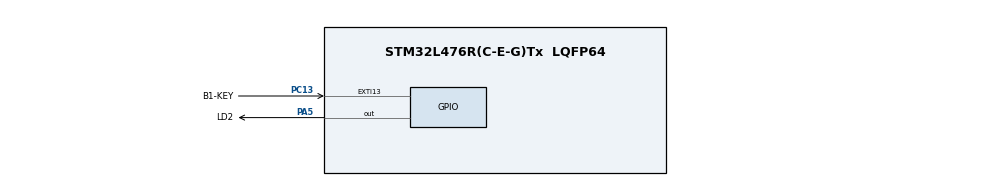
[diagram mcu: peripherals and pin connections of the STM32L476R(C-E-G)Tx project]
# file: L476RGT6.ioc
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FREERTOS.Tasks01=Start_Task,0,128,StartFunc,Default,NULL,Dynamic,NULL,NULL
Mcu.Family=STM32L4
Mcu.Name=STM32L476R(C-E-G)Tx
Mcu.Package=LQFP64
NVIC.PriorityGroup=NVIC_PRIORITYGROUP_4
NVIC.TIM1_UP_TIM16_IRQn=true\:0\:0\:false\:false\:true\:false\:false
NVIC.TimeBase=TIM1_UP_TIM16_IRQn
NVIC.TimeBaseIP=TIM1
PA5.GPIO_Label=LD2
PA5.GPIO_Speed=GPIO_SPEED_FREQ_MEDIUM
PA5.Signal=GPIO_Output
PC13.GPIO_Label=B1-KEY
PC13.GPIO_ModeDefaultEXTI=GPIO_MODE_IT_FALLING
PC13.Signal=GPXTI13
ProjectManager.HeapSize=0x200
ProjectManager.StackSize=0x400
ProjectManager.TargetToolchain=MDK-ARM V5
RCC.ADCFreq_Value=64000000
RCC.AHBFreq_Value=80000000
RCC.APB1Freq_Value=80000000
RCC.APB1TimFreq_Value=80000000
RCC.APB2Freq_Value=80000000
RCC.APB2TimFreq_Value=80000000
RCC.CortexFreq_Value=80000000
RCC.HCLKFreq_Value=80000000
RCC.HSE_VALUE=8000000
RCC.HSI_VALUE=16000000
RCC.LSE_VALUE=32768
RCC.MSI_VALUE=4000000
RCC.PLLN=10
RCC.PLLSourceVirtual=RCC_PLLSOURCE_HSI
RCC.SYSCLKFreq_VALUE=80000000
RCC.SYSCLKSource=RCC_SYSCLKSOURCE_PLLCLK
RCC.USBFreq_Value=64000000
RCC.VCOOutputFreq_Value=160000000
VP_FREERTOS_VS_ENABLE.Mode=Enabled
VP_SYS_VS_tim1.Mode=TIM1
board=custom

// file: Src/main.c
/**
  ******************************************************************************
  * @file           : main.c
  * @brief          : Main program body
  ******************************************************************************
  * This notice applies to any and all portions of this file
  * that are not between comment pairs USER CODE BEGIN and
  * USER CODE END. Other portions of this file, whether
  * inserted by the user or by software development tools
  * are owned by their respective copyright owners.
  *
  * Copyright (c) 2018 STMicroelectronics International N.V.
  * All rights reserved.
  *
  * Redistribution and use in source and binary forms, with or without
  * modification, are permitted, provided that the following conditions are met:
  *
  * 1. Redistribution of source code must retain the above copyright notice,
  *    this list of conditions and the following disclaimer.
  * 2. Redistributions in binary form must reproduce the above copyright notice,
  *    this list of conditions and the following disclaimer in the documentation
  *    and/or other materials provided with the distribution.
  * 3. Neither the name of STMicroelectronics nor the names of other
  *    contributors to this software may be used to endorse or promote products
  *    derived from this software without specific written permission.
  * 4. This software, including modifications and/or derivative works of this
  *    software, must execute solely and exclusively on microcontroller or
  *    microprocessor devices manufactured by or for STMicroelectronics.
  * 5. Redistribution and use of this software other than as permitted under
  *    this license is void and will automatically terminate your rights under
  *    this license.
  *
  * THIS SOFTWARE IS PROVIDED BY STMICROELECTRONICS AND CONTRIBUTORS "AS IS"
  * AND ANY EXPRESS, IMPLIED OR STATUTORY WARRANTIES, INCLUDING, BUT NOT
  * LIMITED TO, THE IMPLIED WARRANTIES OF MERCHANTABILITY, FITNESS FOR A
  * PARTICULAR PURPOSE AND NON-INFRINGEMENT OF THIRD PARTY INTELLECTUAL PROPERTY
  * RIGHTS ARE DISCLAIMED TO THE FULLEST EXTENT PERMITTED BY LAW. IN NO EVENT
  * SHALL STMICROELECTRONICS OR CONTRIBUTORS BE LIABLE FOR ANY DIRECT, INDIRECT,
  * INCIDENTAL, SPECIAL, EXEMPLARY, OR CONSEQUENTIAL DAMAGES (INCLUDING, BUT NOT
  * LIMITED TO, PROCUREMENT OF SUBSTITUTE GOODS OR SERVICES; LOSS OF USE, DATA,
  * OR PROFITS; OR BUSINESS INTERRUPTION) HOWEVER CAUSED AND ON ANY THEORY OF
  * LIABILITY, WHETHER IN CONTRACT, STRICT LIABILITY, OR TORT (INCLUDING
  * NEGLIGENCE OR OTHERWISE) ARISING IN ANY WAY OUT OF THE USE OF THIS SOFTWARE,
  * EVEN IF ADVISED OF THE POSSIBILITY OF SUCH DAMAGE.
  *
  ******************************************************************************
  */
#include "main.h"
#include "stm32l4xx_hal.h"
#include "cmsis_os.h"
#include "gpio.h"

/* USER CODE BEGIN PV */
/* Private variables ---------------------------------------------------------*/

/* USER CODE END PV */

void SystemClock_Config(void);
void MX_FREERTOS_Init(void);

/* USER CODE BEGIN PFP */
/* Private function prototypes -----------------------------------------------*/

/* USER CODE END PFP */

int main(void)
{

  /* MCU Configuration----------------------------------------------------------*/

  /* Reset of all peripherals, Initializes the Flash interface and the Systick. */
  HAL_Init();

  /* Configure the system clock */
  SystemClock_Config();

  /* Initialize all configured peripherals */
  MX_GPIO_Init();

  /* Call init function for freertos objects (in freertos.c) */
  MX_FREERTOS_Init();

  /* Start scheduler */
  osKernelStart();

  /* We should never get here as control is now taken by the scheduler */

  /* Infinite loop */
  while (1)
  {

  }

}

void SystemClock_Config(void)
{

  LL_FLASH_SetLatency(LL_FLASH_LATENCY_4);

  if(LL_FLASH_GetLatency() != LL_FLASH_LATENCY_4)
  {
  Error_Handler();
  }
  LL_PWR_SetRegulVoltageScaling(LL_PWR_REGU_VOLTAGE_SCALE1);

  LL_RCC_HSI_Enable();

   /* Wait till HSI is ready */
  while(LL_RCC_HSI_IsReady() != 1)
  {

  }
  LL_RCC_HSI_SetCalibTrimming(16);

  LL_RCC_PLL_ConfigDomain_SYS(LL_RCC_PLLSOURCE_HSI, LL_RCC_PLLM_DIV_1, 10, LL_RCC_PLLR_DIV_2);

  LL_RCC_PLL_EnableDomain_SYS();

  LL_RCC_PLL_Enable();

   /* Wait till PLL is ready */
  while(LL_RCC_PLL_IsReady() != 1)
  {

  }
  LL_RCC_SetSysClkSource(LL_RCC_SYS_CLKSOURCE_PLL);

   /* Wait till System clock is ready */
  while(LL_RCC_GetSysClkSource() != LL_RCC_SYS_CLKSOURCE_STATUS_PLL)
  {

  }
  LL_RCC_SetAHBPrescaler(LL_RCC_SYSCLK_DIV_1);

  LL_RCC_SetAPB1Prescaler(LL_RCC_APB1_DIV_1);

  LL_RCC_SetAPB2Prescaler(LL_RCC_APB2_DIV_1);

  LL_Init1msTick(80000000);

  LL_SYSTICK_SetClkSource(LL_SYSTICK_CLKSOURCE_HCLK);

  LL_SetSystemCoreClock(80000000);

  /* SysTick_IRQn interrupt configuration */
  NVIC_SetPriority(SysTick_IRQn, NVIC_EncodePriority(NVIC_GetPriorityGrouping(),15, 0));
}

void HAL_TIM_PeriodElapsedCallback(TIM_HandleTypeDef *htim)
{
  if (htim->Instance == TIM1) {
    HAL_IncTick();
  }
}

void _Error_Handler(char *file, int line)
{
  while(1)
  {
  }
}

/************************ (C) COPYRIGHT STMicroelectronics *****END OF FILE****/

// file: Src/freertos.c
/**
  ******************************************************************************
  * File Name          : freertos.c
  * Description        : Code for freertos applications
  ******************************************************************************
  * This notice applies to any and all portions of this file
  * that are not between comment pairs USER CODE BEGIN and
  * USER CODE END. Other portions of this file, whether
  * inserted by the user or by software development tools
  * are owned by their respective copyright owners.
  *
  * Copyright (c) 2018 STMicroelectronics International N.V.
  * All rights reserved.
  *
  * Redistribution and use in source and binary forms, with or without
  * modification, are permitted, provided that the following conditions are met:
  *
  * 1. Redistribution of source code must retain the above copyright notice,
  *    this list of conditions and the following disclaimer.
  * 2. Redistributions in binary form must reproduce the above copyright notice,
  *    this list of conditions and the following disclaimer in the documentation
  *    and/or other materials provided with the distribution.
  * 3. Neither the name of STMicroelectronics nor the names of other
  *    contributors to this software may be used to endorse or promote products
  *    derived from this software without specific written permission.
  * 4. This software, including modifications and/or derivative works of this
  *    software, must execute solely and exclusively on microcontroller or
  *    microprocessor devices manufactured by or for STMicroelectronics.
  * 5. Redistribution and use of this software other than as permitted under
  *    this license is void and will automatically terminate your rights under
  *    this license.
  *
  * THIS SOFTWARE IS PROVIDED BY STMICROELECTRONICS AND CONTRIBUTORS "AS IS"
  * AND ANY EXPRESS, IMPLIED OR STATUTORY WARRANTIES, INCLUDING, BUT NOT
  * LIMITED TO, THE IMPLIED WARRANTIES OF MERCHANTABILITY, FITNESS FOR A
  * PARTICULAR PURPOSE AND NON-INFRINGEMENT OF THIRD PARTY INTELLECTUAL PROPERTY
  * RIGHTS ARE DISCLAIMED TO THE FULLEST EXTENT PERMITTED BY LAW. IN NO EVENT
  * SHALL STMICROELECTRONICS OR CONTRIBUTORS BE LIABLE FOR ANY DIRECT, INDIRECT,
  * INCIDENTAL, SPECIAL, EXEMPLARY, OR CONSEQUENTIAL DAMAGES (INCLUDING, BUT NOT
  * LIMITED TO, PROCUREMENT OF SUBSTITUTE GOODS OR SERVICES; LOSS OF USE, DATA,
  * OR PROFITS; OR BUSINESS INTERRUPTION) HOWEVER CAUSED AND ON ANY THEORY OF
  * LIABILITY, WHETHER IN CONTRACT, STRICT LIABILITY, OR TORT (INCLUDING
  * NEGLIGENCE OR OTHERWISE) ARISING IN ANY WAY OUT OF THE USE OF THIS SOFTWARE,
  * EVEN IF ADVISED OF THE POSSIBILITY OF SUCH DAMAGE.
  *
  ******************************************************************************
  */

#include "FreeRTOS.h"
#include "task.h"
#include "cmsis_os.h"

osThreadId Start_TaskHandle;

void StartFunc(void const * argument);

void MX_FREERTOS_Init(void); /* (MISRA C 2004 rule 8.1) */

/* Hook prototypes */

/* Init FreeRTOS */

void MX_FREERTOS_Init(void) {

  /* Create the thread(s) */
  /* definition and creation of Start_Task */
  osThreadDef(Start_Task, StartFunc, osPriorityNormal, 0, 128);
  Start_TaskHandle = osThreadCreate(osThread(Start_Task), NULL);

}

/* StartFunc function */
void StartFunc(void const * argument)
{

  /* USER CODE BEGIN StartFunc */
  /* Infinite loop */
  for(;;)
  {
	  LL_GPIO_TogglePin(LD2_GPIO_Port, LD2_Pin);
    osDelay(100);
  }
  /* USER CODE END StartFunc */
}

/************************ (C) COPYRIGHT STMicroelectronics *****END OF FILE****/
